# alb32r003x register map
Vendor: ALB; Series: ALB RT SoC
CPU: ALB XF, little endian
Registers are 32-bit, access not given, reset 0x0 unless marked. A register's access mark holds for its fields unless they carry their own. Offsets are from the block's base; [hi:lo] are bit positions; {n}, {i} and the like mark numbered series; 'fields as' and 'values as' point back to an identical list.

## SYSCTL — SYSCTL: System Control block for global device configuration, reset handling, and clock distribution management.
Base 0x29001000
? OPTION_BYTE8 reset 0xFFFFFFFF — OPTION_BYTE8: Option-byte 8 register storing user boot, security and flash-protection settings
{0x0+4i} REUSE{i} (i=0..34) — REUSE{i}: Reuse configuration register {i} for remapping peripherals or test functions
{0x8C+4i} GPIO{i}_DEBOUNCE_VAL (i=0..4) — GPIO{i}_DEBOUNCE_VAL: GPIO{i} debounce-timer value register setting the glitch-filter duration in clock cycles
0xC0 XFLASHC — XFLASHC: External flash controller for high-speed read, program and erase operations
0x100 MSPI_CFG rw — MSPI_CFG: Master Serial Peripheral Interface configuration register for clock, mode and frame settings
  [31] mspi_io_en — 1:MSPI 0:XFLASHC
    1=MSPI; 0=XFLASHC
0x100 GPIO5_DEBOUNCE_VAL — GPIO5_DEBOUNCE_VAL: GPIO5 debounce-timer value register setting the glitch-filter duration in clock cycles
{0x13C+4i} BSPI{i}_CFG rw (i=1..4) — BSPI{i}_CFG: Bridge SPI {i} configuration register for slave-select polarity, speed and protocol parameters
  [0] bspi{i} — BSPI{i} mode control.
    1=MASTER; 0=SLAVE
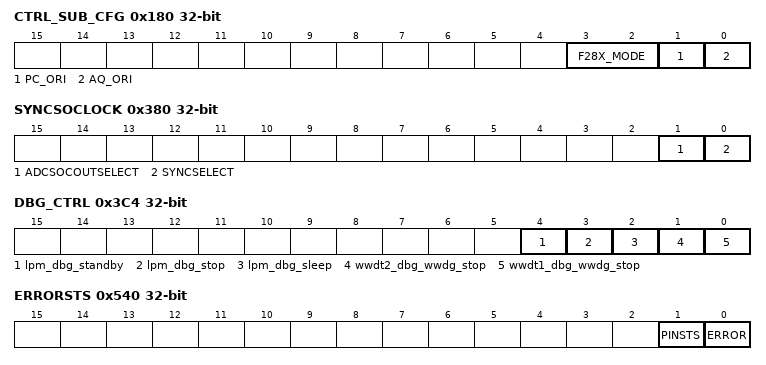
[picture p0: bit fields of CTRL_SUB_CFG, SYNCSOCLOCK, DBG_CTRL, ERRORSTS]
0x180 CTRL_SUB_CFG rw — CTRL_SUB_CFG: Sub-system control configuration register for clock gating, reset and power modes
  [3:2] F28X_MODE
    0=0039mode; 1=P55 (P55mode); 2=P65 (P65mode); 3=P65 (P65mode)
  [1] PC_ORI — 1:function 0:TI function
    1=ONE (function); 0=ZERO (TI function)
  [0] AQ_ORI — 1:function 0:TI function
    1=ONE (function); 0=ZERO (TI function)
0x1C0 SMCM_CFG — SMCM_CFG: Secure Memory Control Module configuration register for access permission and region setup
0x1C4 SMCM_HWINT — SMCM_HWINT: Secure memory control hardware-interrupt status and clear register
0x1C8 SMCM_ECC_ERR — SMCM_ECC_ERR: Secure memory ECC error status register logging single-bit and double-bit fault addresses
0x200 CORE2_CFG1 reset 0x1 — CORE2_CFG1: Core 2 configuration register 1 for initial boot mode and vector remap settings
0x204 CORE2_CFG2 reset 0x2000000 — CORE2_CFG2: Core 2 configuration register 2 for cache enable, endianness and debug options
0x208 CORE_NMI_WK_EN — CORE_NMI_WK_EN: Core non-maskable interrupt wake-up enable register for low-power exit sources
0x240 MTX4_CFG rw — MTX4_CFG: Matrix 4 crossbar configuration register for peripheral interconnect routing
  [3:0] MTX4_REMAP — Bus multiplexing. It can be configured with three values: 0000, 0010, and 0100
    0=EFLASHC; 1=XFLASHC
{0x27C+4i} EQEP{i}_CFG (i=1..3) — EQEP{i}_CFG: Enhanced Quadrature Encoder Pulse unit {i} configuration register for phase, count and filter settings
{0x2BC+4i} ECAP{i}_SYNCSEL (i=1..4) — ECAP{i}_SYNCSEL: ECAP1 sync-source select register routing trigger or sync signals to capture unit {i}
0x300 TIMERx_STAT — TIMERx_STAT: General-purpose Timer status register indicating overflow, compare-match and capture events
{0x300+4i} TIMER{i}_PRESC (i=1..4) — TIMER{i}_PRESC: General-purpose Timer {i} prescaler register for coarse clock division
{0x33C+4i} EPWM{i}SYNCSEL reset 0x1 (i=1..12) — EPWM{i}SYNCSEL: EPWM{i} external sync-source select register routing global sync or phase-shift triggers
0x370 ADCSOCAOUTSELECT rw — ADCSOCAOUTSELECT: ADC start-of-conversion A output-select register mapping SOC triggers to ADC channels
  [30:0] PWMx_SOCAEN — ADCSOCBOn source selection
    0=NO (The corresponding EPWM SOCA output was not selected); 1=YES (Select the corresponding EPWM SOCA output)
0x374 ADCSOCBOUTSELECT rw — ADCSOCBOUTSELECT: ADC start-of-conversion B output-select register mapping SOC triggers to ADC channels
  [30:0] PWMx_SOCBEN — ADCSOCBOn source selection
    0=NO (The corresponding EPWM SOCB output was not selected); 1=YES (Select the corresponding EPWM SOCB output)
0x378 PCLKCRD rw — PCLKCRD: Peripheral clock-control register D enabling or disabling clocks to device sub-modules
  [0] CLKEN_HRPWM — HRPWM clock enable bit: When set, this bit will enable the clock of the HRPWM module.
    1=ENABLED (Enable HRPWM clock); 0=DISABLED (Disable HRPWM clock)
0x37C SYNCSELECT — SYNCSELECT: Global sync-source selection register routing triggers across timers, PWM and capture units
0x380 BOOT_MODE — BOOT_MODE: Boot-mode configuration register defining start-up source, security level and vector remap
0x380 SYNCSOCLOCK rw — SYNCSOCLOCK: Synchronous SOC lock register ensuring atomic access to shared system resources
  [1] ADCSOCOUTSELECT — The lock bit of the ADCSOCOUTSELECT register
    0=NOTLOCKED (The corresponding register is not locked); 1=LOCKED (The corresponding registers have been locked)
  [0] SYNCSELECT — SYNCSELECT register lock bit
    values as ADCSOCOUTSELECT
0x3C0 DBG_CFG — DBG_CFG: Debug configuration register controlling CPU halt, trace enable and peripheral visibility settings
0x3C4 DBG_CTRL rw — DBG_CTRL: Debug control register enabling CPU halt, trace export and peripheral visibility
  [4] lpm_dbg_standby — The system enters debugmode under standby
    1=ON (The CPU clock is on, and the peripheral clock is on); 0=NOT (The CPU clock is not controlled by this signal)
  [3] lpm_dbg_stop — The system enters debugmode under stop
    values as lpm_dbg_standby
  [2] lpm_dbg_sleep — The system enters debugmode under sleep
    1=ON (The CPU clock is on); 0=NOT (The CPU clock is not controlled by this signal)
  [1] wwdt2_dbg_wwdg_stop — The wwdt2 timer will stop
    0=NO (No influence); 1=STOP (The wwdt2 timer has stopped)
  [0] wwdt1_dbg_wwdg_stop — The wwdt1 timer will stop
    0=NO (No influence); 1=STOP (The wwdt1 timer has stopped)
0x400 LPM_CFG — LPM_CFG: Low-power mode configuration register selecting sleep, stop or standby sequences and wake-up sources
0x440 DCC_CFGR — DCC_CFGR: Dual-Clock Comparator configuration register for clock accuracy monitoring and error detection
0x480 INTERNALTESTCTL — INTERNALTESTCTL: Internal-test control register enabling built-in self-test modes and diagnostic loops
0x484 CONFIGLOCK — CONFIGLOCK: Configuration-lock register protecting critical system registers from accidental or unauthorized writes
0x488 TSBSCTL — TSBSCTL: Temperature-sensor bias control register for offset and gain trimming
0x48C ANAREFCTL rw reset 0x1 — ANAREFCTL: Analog reference control register selecting internal or external reference voltage and buffering
  [10:0] ANAREFCTL — Reference voltage source control, external rst reset
    0=INTERSWITCH (Switching between internal and external reference voltage modes); 1=TEMP (Selection of temperature compensation mode); 2=REDUCE (Reduce trim time); 8=SWITCH (1.65V - 2.5V internal reference voltage switching)
0x490 VMONCTL reset 0x100 — VMONCTL: Voltage-monitor control register configuring supply-rail thresholds and brown-out detection
{0x490+4i} CMPHPMXSEL_{i} (i=1..4) — CMPHPMXSEL_{i}: Comparator high-precision multiplexer select {i} for routing analog inputs to comparator channels
0x4A4 ADCDACLOOPBACK — ADCDACLOOPBACK: ADC-to-DAC internal loopback control for self-test and calibration
0x4A8 LOCK rw — LOCK: Global write-lock register preventing accidental modification of critical configuration
  [9:0] LOCK — A single write operation locks the corresponding analogsub register
    0=TSNSCTL; 1=ANAREFCTL; 2=VMONCTL; 3=NONE; 4=NONE; 5=CMPHPMXSEL; 6=CMPLPMXSEL; 7=CMPHNMXSEL; 8=CMPLNMXSEL; 9=VREGCTL
0x4AC AGPIOCTRLA — AGPIOCTRLA: Analog GPIO bank A control for analog/digital mode and slew-rate selection
0x4C0 OB_SEL rw — OB_SEL: Option-byte select register choosing active configuration set
  [0] option_byte_sel
    0=DEFAULT (By default, option byte from EFLASHC or XFLASHC is used); 1=OPTION (Use sysctl to provide option byte)
0x4C4 OPTION_BYTE0 reset 0x68206820 — OPTION_BYTE0: Option-byte 0 register storing user boot, security and flash-protection settings
0x4C8 OPTION_BYTE1 reset 0x82082C01 — OPTION_BYTE1: Option-byte 1 register storing user boot, security and flash-protection settings
0x4CC OPTION_BYTE2 reset 0x1E0A — OPTION_BYTE2: Option-byte 2 register storing user boot, security and flash-protection settings
0x4D0 OPTION_BYTE3 reset 0xA100200 — OPTION_BYTE3: Option-byte 3 register storing user boot, security and flash-protection settings
0x4D4 OPTION_BYTE4 reset 0x5A000000 — OPTION_BYTE4: Option-byte 4 register storing user boot, security and flash-protection settings
{0x4C4+4i} OPTION_BYTE{i} (i=5..7) — OPTION_BYTE{i}: Option-byte {i} register storing user boot, security and flash-protection settings
{0x4C4+4i} OPTION_BYTE{i} reset 0xFFFFFFFF (i=9..11) — OPTION_BYTE{i}: Option-byte {i} register storing user boot, security and flash-protection settings
0x500 WDT_SPEED_UP — WDT_SPEED_UP: Watch-dog timer speed-up register for accelerated timeout during debug or test modes
0x540 ERRORSTS ro — ERRORSTS: Global error status register capturing the first detected fault across all sub-modules
  [1] PINSTS
    0=ZERO (Error Pin is 0); 1=ONE (Error Pin is 1)
  [0] ERROR — Error status
    0=NO (No error source triggers); 1=ERROR (One or more error sources are triggered, or the ERRORSTRS.ERROR bit is set by writing 1); 0=NO (No effect); 1=ERROR (Set ERRORSTS.ERROR to 0); 0=NO (No effect); 1=ERROR (Set ERRORSTS.ERROR to 1)
0x544 ERRORSTSCLR ro — ERRORSTSCLR: Error-status clear register for software acknowledgment and reset of fault flags
  [0] ERROR — Error status
    values as ERRORSTS.ERROR
0x548 ERRORSTSFRC ro — ERRORSTSFRC: Error-status force register for fault-injection testing and diagnostic coverage
  fields as ERRORSTSCLR
0x54C ERRORCTL — ERRORCTL: Error-control register selecting fault response modes and interrupt routing
0x550 ERRORLOCK rw — ERRORLOCK: Error-system lock register protecting all error-related registers from unintended writes
  [0] ERRORCTL
    0=ENABLED (Write to the ERRORCTL register); 1=DISABLED (Prohibit writing to the ERRORCTL register)
0x580 CMPSS_CFG reset 0xFFFF — CMPSS_CFG: Comparator sub-system configuration register for reference, hysteresis and filter setup
0x5C0 DACC_CFG reset 0xFF — DACC_CFG: Digital-to-analog converter configuration register for reference, buffer and output mode
{0x600+4i} PE{i} (i=0..3) — PE{i}: GPIO{i} pull-enable register activating internal pull-up or pull-down resistor
{0x620+4i} PS{i} (i=0..3) — PS{i}: GPIO{i} pull-select register choosing pull-up (1) or pull-down (0) direction
{0x640+4i} IS{i} (i=0..3) — IS{i}: GPIO{i} interrupt-sense register selecting edge or level detection for wake-up events
{0x660+4i} DR{i} reset 0x2 (i=0..6) — DR{i}: GPIO{i} data register providing read/write access to pin state and output latch
{0x800+4i} QUAL_PRD{i} (i=0..23) — QUAL_PRD{i}: GPIO{i} qualification-period register defining the sampling interval for input validation
{0x860+4i} QUAL_MODE{i} (i=0..5) — QUAL_MODE{i}: GPIO{i} qualification-mode register selecting 3-sample majority or synchronizer-only filtering
{0x878+4i} INPUT_INV{i} (i=0..3) — INPUT_INV{i}: GPIO{i} input-inversion register enabling or disabling active-low polarity on the pin
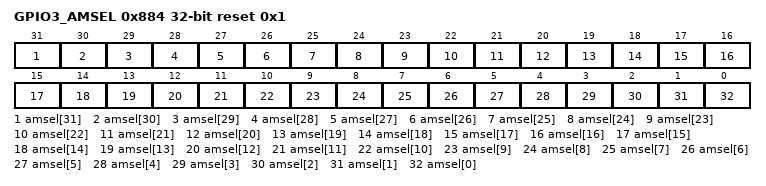
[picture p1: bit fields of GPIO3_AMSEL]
0x884 GPIO3_AMSEL rw reset 0x1 — GPIO3_AMSEL: GPIO3 analog-mode-select register switching between digital I/O and analog functions
  [all] fields
    1=SIMULATION (Simulation mode); 0=DIGITAL (Digital mode)
  [31] amsel[31] — PAD simulation mode enabled
  [30] amsel[30]
  [29] amsel[29] — PAD simulation mode enabled
  [28] amsel[28]
  [27] amsel[27] — PAD simulation mode enabled
  [26] amsel[26]
  [25] amsel[25] — PAD simulation mode enabled
  [24] amsel[24]
  [23] amsel[23] — PAD simulation mode enabled
  [22] amsel[22]
  [21] amsel[21] — PAD simulation mode enabled
  [20] amsel[20]
  [19] amsel[19] — PAD simulation mode enabled
  [18] amsel[18]
  [17] amsel[17] — PAD simulation mode enabled
  [16] amsel[16]
  [15] amsel[15] — PAD simulation mode enabled
  [14] amsel[14] — PAD simulation mode enabled
  [13] amsel[13]
  [12] amsel[12] — PAD simulation mode enabled
  [11] amsel[11]
  [10] amsel[10] — PAD simulation mode enabled
  [9] amsel[9]
  [8] amsel[8] — PAD simulation mode enabled
  [7] amsel[7]
  [6] amsel[6] — PAD simulation mode enabled
  [5] amsel[5]
  [4] amsel[4] — PAD simulation mode enabled
  [3] amsel[3]
  [2] amsel[2] — PAD simulation mode enabled
  [1] amsel[1]
  [0] amsel[0] — PAD simulation mode enabled
